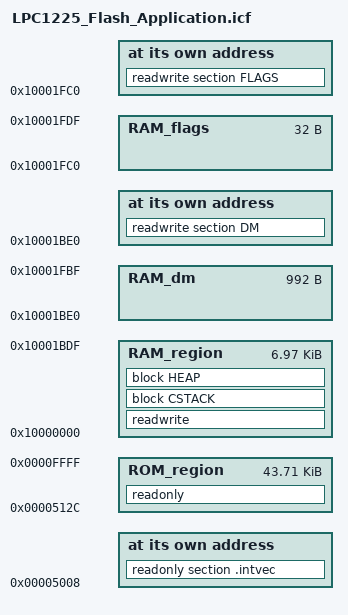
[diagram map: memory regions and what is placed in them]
/*###ICF### Section handled by ICF editor, don't touch! ****/
/*-Editor annotation file-*/
/* IcfEditorFile="$TOOLKIT_DIR$\config\ide\IcfEditor\cortex_v1_0.xml" */
/*-Specials-*/
define symbol __ICFEDIT_intvec_start__ = 0x00005008;
/*-Memory Regions-*/
define symbol __ICFEDIT_region_ROM_start__   = 0x0000512C;
define symbol __ICFEDIT_region_ROM_end__     = 0x0000FFFF;
/*-Sizes-*/
define symbol __ICFEDIT_size_cstack__   = 0x600;
define symbol __ICFEDIT_size_heap__     = 0x400;
/**** End of ICF editor section. ###ICF###*/


define memory mem with size = 4G;

define region ROM_region    = mem:  [from __ICFEDIT_region_ROM_start__  to __ICFEDIT_region_ROM_end__   ];


/* RAM area for dynamic allocation */
define symbol __RAM_DM_START__          = 0x10001BE0;   
define symbol __RAM_DM_END__            = 0x10001FBF;   // DO NOT CHANGE!!

/* RAM regions */
define symbol __RAM_NORMAL_START__      = 0x10000000;
define symbol __RAM_NORMAL_END__        = __RAM_DM_START__ - 1;       // change this and make more space for dynamic buffer 

/* RAM area for flags, redirection pointer, etc... */
define symbol __RAM_FLAGS_START__       = 0x10001FC0;   // DO NOT CHANGE!!
define symbol __RAM_FLAGS_END__         = 0x10001FDF;   // DO NOT CHANGE!!

define region RAM_region        = mem:[from __RAM_NORMAL_START__    to __RAM_NORMAL_END__   ];
define region RAM_dm            = mem:[from __RAM_DM_START__        to __RAM_DM_END__       ];
define region RAM_flags         = mem:[from __RAM_FLAGS_START__     to __RAM_FLAGS_END__    ];

define block CSTACK    with alignment = 8, size = __ICFEDIT_size_cstack__   { };
define block HEAP      with alignment = 8, size = __ICFEDIT_size_heap__     { };

initialize by copy { readwrite };
do not initialize  { section .noinit };

place at address mem:__ICFEDIT_intvec_start__ { readonly section .intvec };
place at address mem: __RAM_DM_START__ { readwrite section DM };
place at address mem: __RAM_FLAGS_START__ { readwrite section FLAGS };
place in ROM_region   { readonly };
place in RAM_region   { readwrite,
                        block CSTACK, block HEAP };

